# EOS-S3 register map
File version: 0.1
CPU: CM4 r0p1, selectable endian, MPU, FPU, 3 interrupt priority bits
Registers are 32-bit, read-write, reset 0x0 unless marked. A register's access mark holds for its fields unless they carry their own. Offsets are from the block's base; [hi:lo] are bit positions; {n}, {i} and the like mark numbered series; 'fields as' and 'values as' point back to an identical list.

## PKFB — Packet FFO Bank control
Base 0x40002000
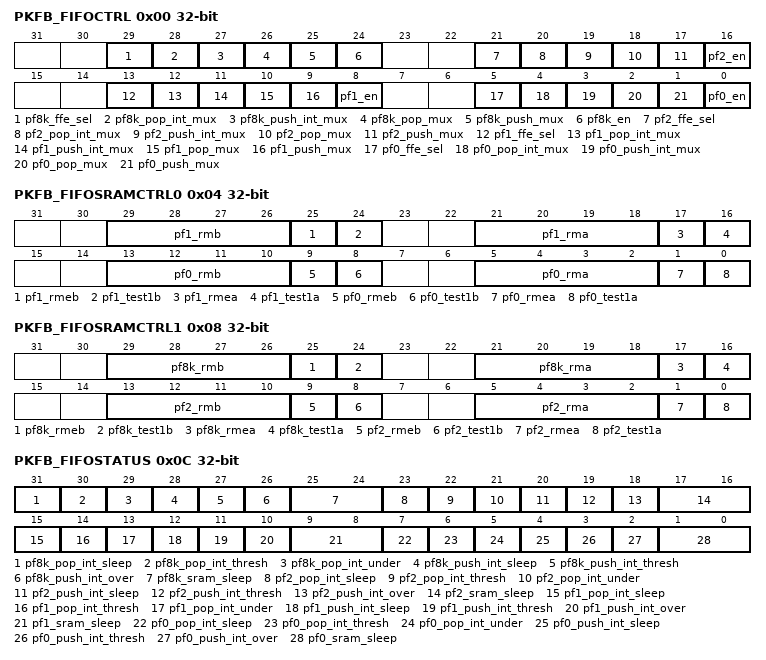
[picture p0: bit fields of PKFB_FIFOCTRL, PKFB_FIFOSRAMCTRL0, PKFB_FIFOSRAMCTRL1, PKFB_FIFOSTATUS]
0x00 PKFB_FIFOCTRL — Packet FIFO Bank control
  [29] pf8k_ffe_sel — If FFE is the controller, select which instance of FFE will be used for control
    0=ffe0 (when FFE is the controller of the FIFO, select FFE0 as the controller); 1=ffe1 (when FFE is the controller of the FIFO, select FFE1 as the controller)
  [28] pf8k_pop_int_mux — Select which subsystem manages the pop interrupt
    0=m4 (Select the M4 subsystem to control the FIFO); 1=ap (Select the AP subsystem to control the FIFO)
  [27] pf8k_push_int_mux — Select which subsystem manages the push interrupt
    values as pf8k_pop_int_mux
  [26] pf8k_pop_mux — Select which subsystem controls the pop operation
    values as pf8k_pop_int_mux
  [25] pf8k_push_mux — Select which subsystem controls the push operation
    0=m4 (Select the M4 subsystem to control the FIFO); 1=ffe (Select the FFE subsystem to control the FIFO)
  [24] pf8k_en — Set to enable the Packet FIFO
    0=Disable the packet FIFO; 1=Enable the packet FIFO
  [21] pf2_ffe_sel — If FFE is the controller, select which instance of FFE will be used for control
    values as pf8k_ffe_sel
  [20] pf2_pop_int_mux — Select which subsystem manages the pop interrupt
    values as pf8k_pop_int_mux
  [19] pf2_push_int_mux — Select which subsystem manages the push interrupt
    values as pf8k_pop_int_mux
  [18] pf2_pop_mux — Select which subsystem controls the pop operation
    values as pf8k_pop_int_mux
  [17] pf2_push_mux — Select which subsystem controls the push operation
    values as pf8k_push_mux
  [16] pf2_en — Set to enable the Packet FIFO
    0=Disable the packet FIFO; 1=Enable the packet FIFO
  [13] pf1_ffe_sel — If FFE is the controller, select which instance of FFE will be used for control
    values as pf8k_ffe_sel
  [12] pf1_pop_int_mux — Select which subsystem manages the pop interrupt
    values as pf8k_pop_int_mux
  [11] pf1_push_int_mux — Select which subsystem manages the push interrupt
    values as pf8k_pop_int_mux
  [10] pf1_pop_mux — Select which subsystem controls the pop operation
    values as pf8k_pop_int_mux
  [9] pf1_push_mux — Select which subsystem controls the push operation
    values as pf8k_push_mux
  [8] pf1_en — Set to enable the Packet FIFO
    0=Disable the packet FIFO; 1=Enable the packet FIFO
  [5] pf0_ffe_sel — If FFE is the controller, select which instance of FFE will be used for control
    values as pf8k_ffe_sel
  [4] pf0_pop_int_mux — Select which subsystem manages the pop interrupt
    values as pf8k_pop_int_mux
  [3] pf0_push_int_mux — Select which subsystem manages the push interrupt
    values as pf8k_pop_int_mux
  [2] pf0_pop_mux — Select which subsystem controls the pop operation
    values as pf8k_pop_int_mux
  [1] pf0_push_mux — Select which subsystem controls the push operation
    values as pf8k_push_mux
  [0] pf0_en — Set to enable the Packet FIFO
    0=Disable the packet FIFO; 1=Enable the packet FIFO
0x04 PKFB_FIFOSRAMCTRL0 — SRAM Test Control 0
  [29:26] pf1_rmb — SRAM Adjust timing value
  [25] pf1_rmeb — Set this bit to disable SRAM timing adjust
  [24] pf1_test1b — Set this bit to disable Test capabilities
  [21:18] pf1_rma — SRAM Adjust timing value
  [17] pf1_rmea — Set this bit to disable SRAM timing adjust
  [16] pf1_test1a — Set this bit to disable Test capabilities
  [13:10] pf0_rmb — SRAM Adjust timing value
  [9] pf0_rmeb — Set this bit to disable SRAM timing adjust
  [8] pf0_test1b — Set this bit to disable Test capabilities
  [5:2] pf0_rma — SRAM Adjust timing value
  [1] pf0_rmea — Set this bit to disable SRAM timing adjust
  [0] pf0_test1a — Set this bit to disable Test capabilities
0x08 PKFB_FIFOSRAMCTRL1 — SRAM Test Control 1
  [29:26] pf8k_rmb — SRAM Adjust timing value
  [25] pf8k_rmeb — Set this bit to disable SRAM timing adjust
  [24] pf8k_test1b — Set this bit to disable Test capabilities
  [21:18] pf8k_rma — SRAM Adjust timing value
  [17] pf8k_rmea — Set this bit to disable SRAM timing adjust
  [16] pf8k_test1a — Set this bit to disable Test capabilities
  [13:10] pf2_rmb — SRAM Adjust timing value
  [9] pf2_rmeb — Set this bit to disable SRAM timing adjust
  [8] pf2_test1b — Set this bit to disable Test capabilities
  [5:2] pf2_rma — SRAM Adjust timing value
  [1] pf2_rmea — Set this bit to disable SRAM timing adjust
  [0] pf2_test1a — Set this bit to disable Test capabilities
0x0C PKFB_FIFOSTATUS — Packet FIFO Status register
  [31] pf8k_pop_int_sleep — Bit is set if there's an interrupt set for pop on SRAM sleep
  [30] pf8k_pop_int_thresh — Bit is set if there's an interrupt set for pop threshold
  [29] pf8k_pop_int_under — Bit is set if there's an interrupt set for underflow
  [28] pf8k_push_int_sleep — Bit is set if there's an interrupt set for push on SRAM sleep
  [27] pf8k_push_int_thresh — Bit is set if there's an interrupt set for push threshold
  [26] pf8k_push_int_over — Bit is set if there's an interrupt set for overflow (pktFIFO or FFE FIFO)
  [25:24] pf8k_sram_sleep — SRAM Sleep Status
    0=active (SRAM is in active mode); 1=light_sleep (SRAM is in Light Sleep mode); 2=deep_sleep (SRAM is in Deep Sleep mode); 3=shutdown (SRAM is in Shutdown mode)
  [23] pf2_pop_int_sleep — Bit is set if there's an interrupt set for pop on SRAM sleep
  [22] pf2_pop_int_thresh — Bit is set if there's an interrupt set for pop threshold
  [21] pf2_pop_int_under — Bit is set if there's an interrupt set for underflow
  [20] pf2_push_int_sleep — Bit is set if there's an interrupt set for push on SRAM sleep
  [19] pf2_push_int_thresh — Bit is set if there's an interrupt set for push threshold
  [18] pf2_push_int_over — Bit is set if there's an interrupt set for overflow (pktFIFO or FFE FIFO)
  [17:16] pf2_sram_sleep — SRAM Sleep Status
    values as pf8k_sram_sleep
  [15] pf1_pop_int_sleep — Bit is set if there's an interrupt set for pop on SRAM sleep
  [14] pf1_pop_int_thresh — Bit is set if there's an interrupt set for pop threshold
  [13] pf1_pop_int_under — Bit is set if there's an interrupt set for underflow
  [12] pf1_push_int_sleep — Bit is set if there's an interrupt set for push on SRAM sleep
  [11] pf1_push_int_thresh — Bit is set if there's an interrupt set for push threshold
  [10] pf1_push_int_over — Bit is set if there's an interrupt set for overflow (pktFIFO or FFE FIFO)
  [9:8] pf1_sram_sleep — SRAM Sleep Status
    values as pf8k_sram_sleep
  [7] pf0_pop_int_sleep — Bit is set if there's an interrupt set for pop on SRAM sleep
  [6] pf0_pop_int_thresh — Bit is set if there's an interrupt set for pop threshold
  [5] pf0_pop_int_under — Bit is set if there's an interrupt set for underflow
  [4] pf0_push_int_sleep — Bit is set if there's an interrupt set for push on SRAM sleep
  [3] pf0_push_int_thresh — Bit is set if there's an interrupt set for push threshold
  [2] pf0_push_int_over — Bit is set if there's an interrupt set for overflow (pktFIFO or FFE FIFO)
  [1:0] pf0_sram_sleep — SRAM Sleep Status
    values as pf8k_sram_sleep
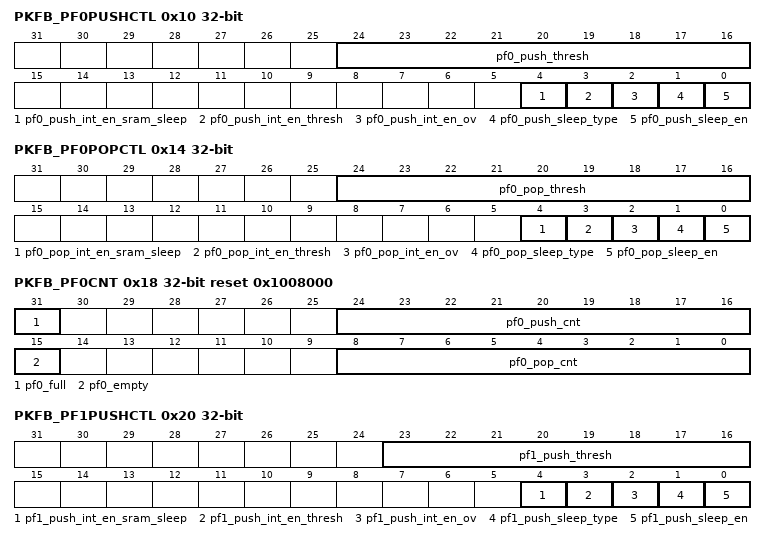
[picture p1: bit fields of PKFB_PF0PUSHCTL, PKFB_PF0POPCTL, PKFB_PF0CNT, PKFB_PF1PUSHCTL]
0x10 PKFB_PF0PUSHCTL — FIFO 0 Push Control
  [24:16] pf0_push_thresh — PUSH counter threshold (x32 count)
  [4] pf0_push_int_en_sram_sleep — Control whether the push interrupt for push on SRAM sleep is enabled or masked
    0=Mask the interrupt event; 1=Unmask the interrupt event
  [3] pf0_push_int_en_thresh — Control whether the push interrupt for FIFO threshold is enabled or masked
    0=Mask the interrupt event; 1=Unmask the interrupt event
  [2] pf0_push_int_en_ov — Control whether the push interrupt for FIFO overflow is enabled or masked
    0=Mask the interrupt event; 1=Unmask the interrupt event
  [1] pf0_push_sleep_type — Select the type of sleep mode
    0=deep_sleep (Select deep sleep as sleep type for the FIFO); 1=shut_down (Select shutdown as the sleep type for the FIFO)
  [0] pf0_push_sleep_en — Set this bit to enable sleep
0x14 PKFB_PF0POPCTL — FIFO 0 Pop Control
  [24:16] pf0_pop_thresh — POP counter threshold (x32 count)
  [4] pf0_pop_int_en_sram_sleep — Control whether the push interrupt for pop on SRAM sleep is enabled or masked
    0=Mask the interrupt event; 1=Unmask the interrupt event
  [3] pf0_pop_int_en_thresh — Control whether the push interrupt for FIFO threshold is enabled or masked
    0=Mask the interrupt event; 1=Unmask the interrupt event
  [2] pf0_pop_int_en_ov — Control whether the push interrupt for FIFO overflow is enabled or masked
    0=Mask the interrupt event; 1=Unmask the interrupt event
  [1] pf0_pop_sleep_type — Select the type of sleep mode
    values as PKFB_PF0PUSHCTL.pf0_push_sleep_type
  [0] pf0_pop_sleep_en — Set this bit to enable sleep
0x18 PKFB_PF0CNT reset 0x1008000 — FIFO 0 Count
  [31] pf0_full ro — FIFO 0 Full
  [24:16] pf0_push_cnt ro — FIFO 0 Push Count (x32 count) Number of available entries for push
  [15] pf0_empty ro — FIFO 0 Empty
  [8:0] pf0_pop_cnt ro — FIFO 0 Pop Count (x32 count) Number of available entries for pop
{0x1C+0x10*i} PKFB_PF{i}DATA (i=0..2) — FIFO {i} Push/POP Data Register
  [31:0] pf{i}_data_reg
0x20 PKFB_PF1PUSHCTL — FIFO 1 Push Control
  [23:16] pf1_push_thresh — PUSH counter threshold (x32 count)
  [4] pf1_push_int_en_sram_sleep — Control whether the push interrupt for push on SRAM sleep is enabled or masked
    0=Mask the interrupt event; 1=Unmask the interrupt event
  [3] pf1_push_int_en_thresh — Control whether the push interrupt for FIFO threshold is enabled or masked
    0=Mask the interrupt event; 1=Unmask the interrupt event
  [2] pf1_push_int_en_ov — Control whether the push interrupt for FIFO overflow is enabled or masked
    0=Mask the interrupt event; 1=Unmask the interrupt event
  [1] pf1_push_sleep_type — Select the type of sleep mode
    values as PKFB_PF0PUSHCTL.pf0_push_sleep_type
  [0] pf1_push_sleep_en — Set this bit to enable sleep
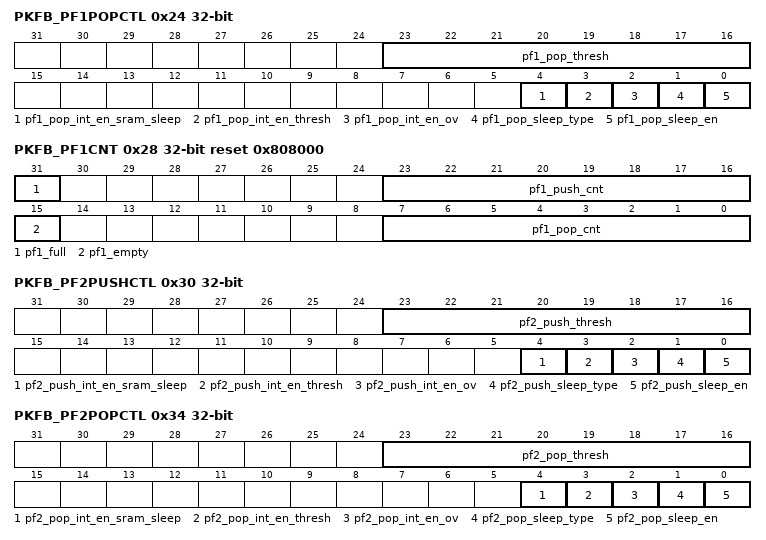
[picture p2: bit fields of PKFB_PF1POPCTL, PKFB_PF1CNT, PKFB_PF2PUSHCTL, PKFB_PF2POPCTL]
0x24 PKFB_PF1POPCTL — FIFO 1 Pop Control
  [23:16] pf1_pop_thresh — POP counter threshold (x32 count)
  [4] pf1_pop_int_en_sram_sleep — Control whether the push interrupt for pop on SRAM sleep is enabled or masked
    0=Mask the interrupt event; 1=Unmask the interrupt event
  [3] pf1_pop_int_en_thresh — Control whether the push interrupt for FIFO threshold is enabled or masked
    0=Mask the interrupt event; 1=Unmask the interrupt event
  [2] pf1_pop_int_en_ov — Control whether the push interrupt for FIFO overflow is enabled or masked
    0=Mask the interrupt event; 1=Unmask the interrupt event
  [1] pf1_pop_sleep_type — Select the type of sleep mode
    values as PKFB_PF0PUSHCTL.pf0_push_sleep_type
  [0] pf1_pop_sleep_en — Set this bit to enable sleep
0x28 PKFB_PF1CNT reset 0x808000 — FIFO 1 Count
  [31] pf1_full ro — FIFO 1 Full
  [23:16] pf1_push_cnt ro — FIFO 1 Push Count (x32 count) Number of available entries for push
  [15] pf1_empty ro — FIFO 1 Empty
  [7:0] pf1_pop_cnt ro — FIFO 1 Pop Count (x32 count) Number of available entries for pop
0x30 PKFB_PF2PUSHCTL — FIFO 2 Push Control
  [23:16] pf2_push_thresh — PUSH counter threshold (x32 count)
  [4] pf2_push_int_en_sram_sleep — Control whether the push interrupt for push on SRAM sleep is enabled or masked
    0=Mask the interrupt event; 1=Unmask the interrupt event
  [3] pf2_push_int_en_thresh — Control whether the push interrupt for FIFO threshold is enabled or masked
    0=Mask the interrupt event; 1=Unmask the interrupt event
  [2] pf2_push_int_en_ov — Control whether the push interrupt for FIFO overflow is enabled or masked
    0=Mask the interrupt event; 1=Unmask the interrupt event
  [1] pf2_push_sleep_type — Select the type of sleep mode
    values as PKFB_PF0PUSHCTL.pf0_push_sleep_type
  [0] pf2_push_sleep_en — Set this bit to enable sleep
0x34 PKFB_PF2POPCTL — FIFO 2 Pop Control
  [23:16] pf2_pop_thresh — POP counter threshold (x32 count)
  [4] pf2_pop_int_en_sram_sleep — Control whether the push interrupt for pop on SRAM sleep is enabled or masked
    0=Mask the interrupt event; 1=Unmask the interrupt event
  [3] pf2_pop_int_en_thresh — Control whether the push interrupt for FIFO threshold is enabled or masked
    0=Mask the interrupt event; 1=Unmask the interrupt event
  [2] pf2_pop_int_en_ov — Control whether the push interrupt for FIFO overflow is enabled or masked
    0=Mask the interrupt event; 1=Unmask the interrupt event
  [1] pf2_pop_sleep_type — Select the type of sleep mode
    values as PKFB_PF0PUSHCTL.pf0_push_sleep_type
  [0] pf2_pop_sleep_en — Set this bit to enable sleep
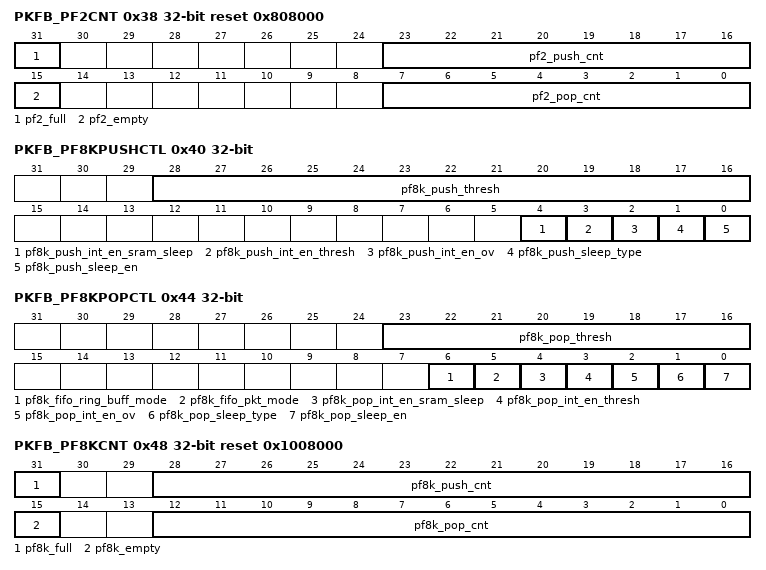
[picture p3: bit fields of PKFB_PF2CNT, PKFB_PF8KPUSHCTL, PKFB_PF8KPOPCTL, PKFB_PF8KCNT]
0x38 PKFB_PF2CNT reset 0x808000 — FIFO 2 Count
  [31] pf2_full ro — FIFO 2 Full
  [23:16] pf2_push_cnt ro — FIFO 2 Push Count (x32 count) Number of available entries for push
  [15] pf2_empty ro — FIFO 2 Empty
  [7:0] pf2_pop_cnt ro — FIFO 2 Pop Count (x32 count) Number of available entries for pop
0x40 PKFB_PF8KPUSHCTL (reset mask 0x1FF001F) — FIFO 8k Push Control
  [28:16] pf8k_push_thresh — PUSH counter threshold (x16 count)
  [4] pf8k_push_int_en_sram_sleep — Control whether the push interrupt for push on SRAM sleep is enabled or masked
    0=Mask the interrupt event; 1=Unmask the interrupt event
  [3] pf8k_push_int_en_thresh — Control whether the push interrupt for FIFO threshold is enabled or masked
    0=Mask the interrupt event; 1=Unmask the interrupt event
  [2] pf8k_push_int_en_ov — Control whether the push interrupt for FIFO overflow is enabled or masked
    0=Mask the interrupt event; 1=Unmask the interrupt event
  [1] pf8k_push_sleep_type — Select the type of sleep mode
    values as PKFB_PF0PUSHCTL.pf0_push_sleep_type
  [0] pf8k_push_sleep_en — Set this bit to enable sleep
0x44 PKFB_PF8KPOPCTL — FIFO 8k Pop Control
  [23:16] pf8k_pop_thresh — POP counter threshold (x16 count)
  [6] pf8k_fifo_ring_buff_mode — Ring buffer mode
  [5] pf8k_fifo_pkt_mode — FIFO Packet Mode
  [4] pf8k_pop_int_en_sram_sleep — Control whether the push interrupt for pop on SRAM sleep is enabled or masked
    0=Mask the interrupt event; 1=Unmask the interrupt event
  [3] pf8k_pop_int_en_thresh — Control whether the push interrupt for FIFO threshold is enabled or masked
    0=Mask the interrupt event; 1=Unmask the interrupt event
  [2] pf8k_pop_int_en_ov — Control whether the push interrupt for FIFO overflow is enabled or masked
    0=Mask the interrupt event; 1=Unmask the interrupt event
  [1] pf8k_pop_sleep_type — Select the type of sleep mode
    values as PKFB_PF0PUSHCTL.pf0_push_sleep_type
  [0] pf8k_pop_sleep_en — Set this bit to enable sleep
0x48 PKFB_PF8KCNT reset 0x1008000 — FIFO 8k Count
  [31] pf8k_full ro — FIFO 8k Full
  [28:16] pf8k_push_cnt ro — FIFO 8k Push Count (x32 count) Number of available entries for push
  [15] pf8k_empty ro — FIFO 8k Empty
  [12:0] pf8k_pop_cnt ro — FIFO 8k Pop Count (x16 count) Number of available entries for pop
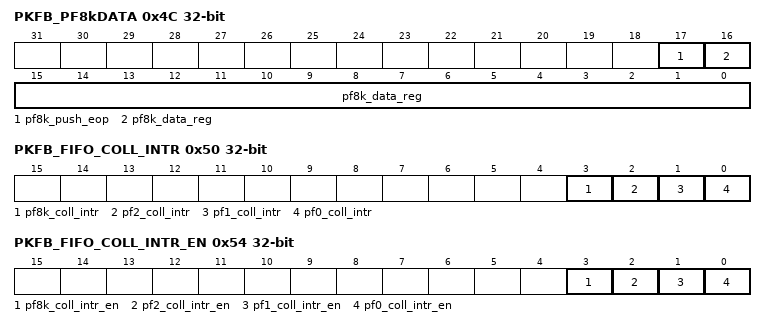
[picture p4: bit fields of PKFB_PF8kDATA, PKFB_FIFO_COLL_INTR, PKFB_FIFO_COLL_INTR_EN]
0x4C PKFB_PF8kDATA — FIFO 8k Push/POP Data Register
  [17] pf8k_push_eop wo — FIFO 8k Push EOP (end of packet)
  [16:0] pf8k_data_reg — FIFO 8k Push/POP Data Register. In ringbuffer mode, [16] is treated as SOP (start-of-packet) by autodrain logic
0x50 PKFB_FIFO_COLL_INTR — Control for collision interrupts
  [3] pf8k_coll_intr — Interrupt is triggered when bot FFE0 and FFE1 try to push into packet FIFO 8k
  [2] pf2_coll_intr — Interrupt is triggered when bot FFE0 and FFE1 try to push into packet FIFO 0
  [1] pf1_coll_intr — Interrupt is triggered when bot FFE0 and FFE1 try to push into packet FIFO 1
  [0] pf0_coll_intr — Interrupt is triggered when bot FFE0 and FFE1 try to push into packet FIFO 0
0x54 PKFB_FIFO_COLL_INTR_EN — Control register for enabling or masking the collisione interrupts
  [all] fields
    0=Mask the interrupt event; 1=Unmask the interrupt event
  [3] pf8k_coll_intr_en — Set bit to enable interrupt
  [2] pf2_coll_intr_en — Set bit to enable interrupt
  [1] pf1_coll_intr_en — Set bit to enable interrupt
  [0] pf0_coll_intr_en — Set bit to enable interrupt
